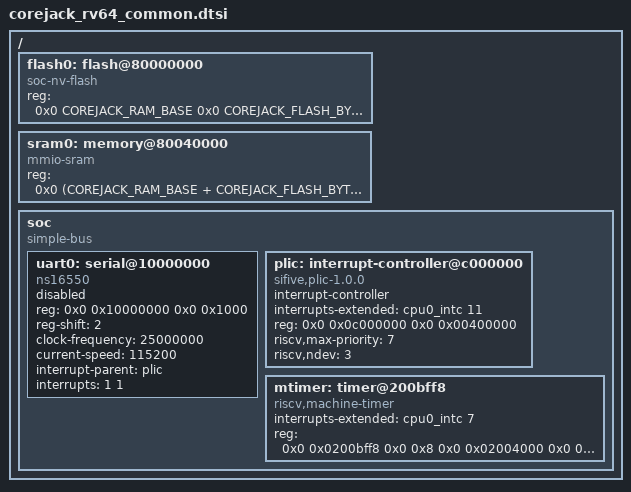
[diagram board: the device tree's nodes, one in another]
#include <skeleton.dtsi>

/*
 * Memory geometry derives from a single source of truth: the total shared SRAM
 * size, COREJACK_RAM_BYTES, comes from cfg/boards/<board>.yaml memory.ram_bytes
 * (passed in by the build via DTS_EXTRA_CPPFLAGS). flash0 is the executable
 * region and sram0 the writable region; both are halves of the one contiguous
 * physical SRAM at COREJACK_RAM_BASE. COREJACK_FLASH_BYTES (the code budget) is
 * the only board-tunable split knob - a board #defines it before including this
 * file when it wants a different split; sram0 takes the remainder. The defaults
 * reproduce the 1 MiB AXKU5 layout. Address/size are two cells each here.
 */
#ifndef COREJACK_RAM_BASE
#define COREJACK_RAM_BASE 0x80000000
#endif
#ifndef COREJACK_RAM_BYTES
#define COREJACK_RAM_BYTES 0x100000
#endif
#ifndef COREJACK_FLASH_BYTES
#define COREJACK_FLASH_BYTES 0x40000
#endif

/ {
	#address-cells = <2>;
	#size-cells = <2>;

	flash0: flash@80000000 {
		compatible = "soc-nv-flash";
		reg = <0x0 COREJACK_RAM_BASE 0x0 COREJACK_FLASH_BYTES>;
	};

	sram0: memory@80040000 {
		device_type = "memory";
		compatible = "mmio-sram";
		reg = <0x0 (COREJACK_RAM_BASE + COREJACK_FLASH_BYTES)
		       0x0 (COREJACK_RAM_BYTES - COREJACK_FLASH_BYTES)>;
	};

	soc {
		#address-cells = <2>;
		#size-cells = <2>;
		compatible = "simple-bus";
		ranges;

		uart0: serial@10000000 {
			compatible = "ns16550";
			reg = <0x0 0x10000000 0x0 0x1000>;
			reg-shift = <2>;
			clock-frequency = <25000000>;
			current-speed = <115200>;
			interrupt-parent = <&plic>;
			interrupts = <1 1>;
			status = "disabled";
		};

		/*
		 * rtl/platform/soc_plic.sv: M-mode, one context (context 0), sources
		 * 1 = UART and 2 = iDMA completion, 3 priority bits, a 4 MiB window.
		 * Zephyr's driver only accepts local IRQ IDs below riscv,ndev, and
		 * ID 0 is reserved, so the two sources need riscv,ndev = 3.
		 */
		plic: interrupt-controller@c000000 {
			compatible = "sifive,plic-1.0.0";
			#address-cells = <0>;
			#interrupt-cells = <2>;
			interrupt-controller;
			interrupts-extended = <&cpu0_intc 11>;
			reg = <0x0 0x0c000000 0x0 0x00400000>;
			riscv,max-priority = <7>;
			riscv,ndev = <3>;
		};

		mtimer: timer@200bff8 {
			compatible = "riscv,machine-timer";
			interrupts-extended = <&cpu0_intc 7>;
			reg = <0x0 0x0200bff8 0x0 0x8 0x0 0x02004000 0x0 0x8>;
			reg-names = "mtime", "mtimecmp";
			status = "okay";
		};
	};
};
